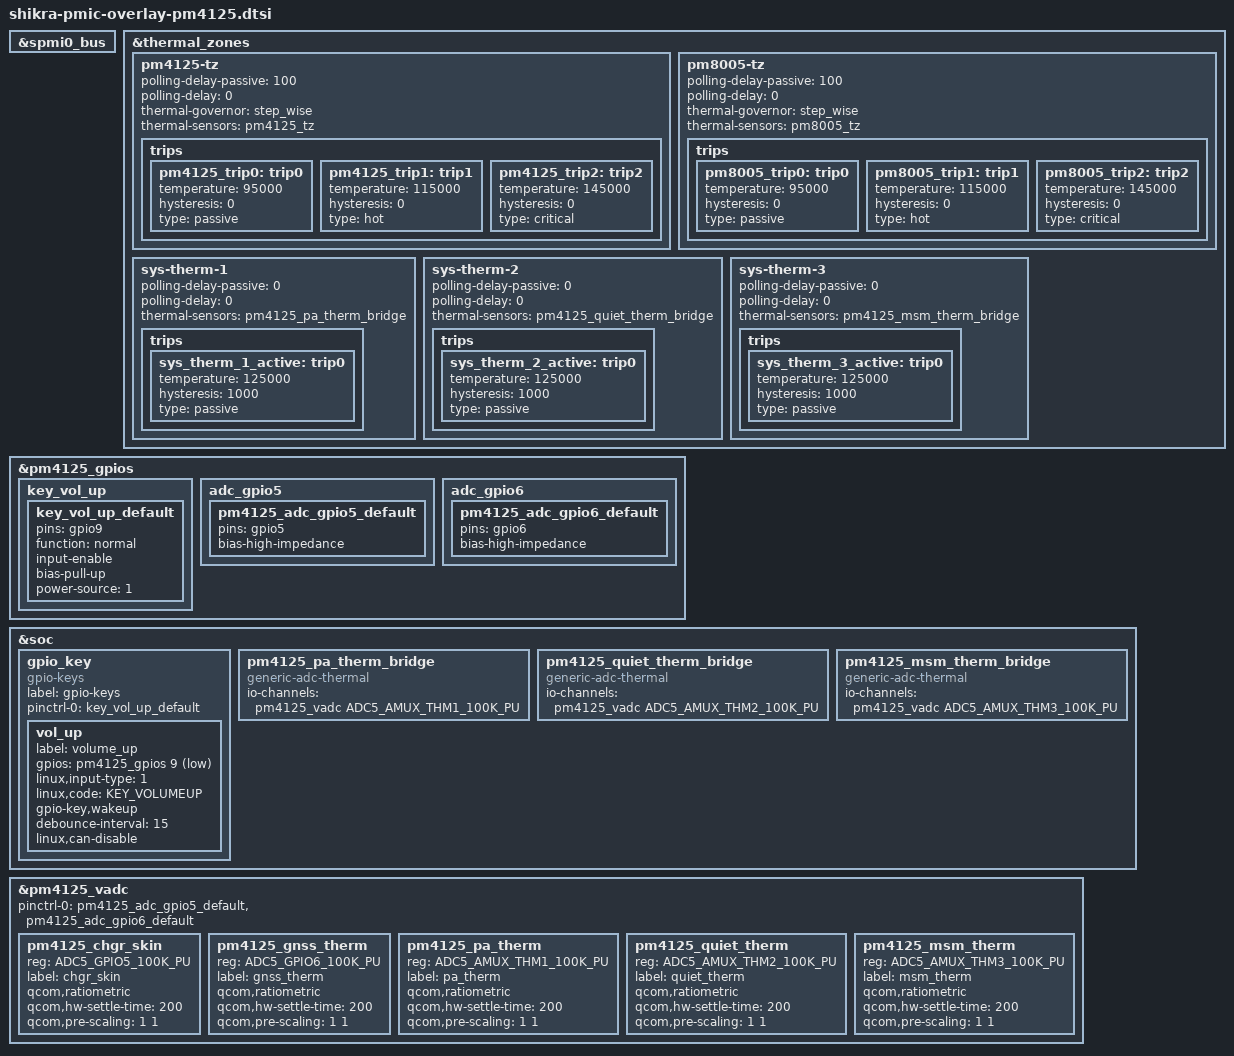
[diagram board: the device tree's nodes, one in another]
// SPDX-License-Identifier: BSD-3-Clause
/*
 * Copyright (c) Qualcomm Technologies, Inc. and/or its subsidiaries.
 */

#include <dt-bindings/gpio/gpio.h>
#include <dt-bindings/input/input.h>
#include <dt-bindings/iio/qcom,spmi-vadc.h>

&spmi0_bus {
	#include "pm4125.dtsi"
	#include "pm8005.dtsi"
};

&thermal_zones {
	pm4125-tz {
		polling-delay-passive = <100>;
		polling-delay = <0>;
		thermal-governor = "step_wise";
		thermal-sensors = <&pm4125_tz>;

		trips {
			pm4125_trip0: trip0 {
				temperature = <95000>;
				hysteresis = <0>;
				type = "passive";
			};

			pm4125_trip1: trip1 {
				temperature = <115000>;
				hysteresis = <0>;
				type = "hot";
			};

			pm4125_trip2: trip2 {
				temperature = <145000>;
				hysteresis = <0>;
				type = "critical";
			};
		};
	};

	pm8005-tz {
		polling-delay-passive = <100>;
		polling-delay = <0>;
		thermal-governor = "step_wise";
		thermal-sensors = <&pm8005_tz>;

		trips {
			pm8005_trip0: trip0 {
				temperature = <95000>;
				hysteresis = <0>;
				type = "passive";
			};

			pm8005_trip1: trip1 {
				temperature = <115000>;
				hysteresis = <0>;
				type = "hot";
			};

			pm8005_trip2: trip2 {
				temperature = <145000>;
				hysteresis = <0>;
				type = "critical";
			};
		};
	};

	sys-therm-1 {
		polling-delay-passive = <0>;
		polling-delay = <0>;
		thermal-sensors = <&pm4125_pa_therm_bridge>;

		trips {
			sys_therm_1_active: trip0 {
				temperature = <125000>;
				hysteresis = <1000>;
				type = "passive";
			};
		};
	};

	sys-therm-2 {
		polling-delay-passive = <0>;
		polling-delay = <0>;
		thermal-sensors = <&pm4125_quiet_therm_bridge>;

		trips {
			sys_therm_2_active: trip0 {
				temperature = <125000>;
				hysteresis = <1000>;
				type = "passive";
			};
		};
	};

	sys-therm-3 {
		polling-delay-passive = <0>;
		polling-delay = <0>;
		thermal-sensors = <&pm4125_msm_therm_bridge>;

		trips {
			sys_therm_3_active: trip0 {
				temperature = <125000>;
				hysteresis = <1000>;
				type = "passive";
			};
		};
	};
};

&pm4125_gpios {
	key_vol_up {
		key_vol_up_default: key_vol_up_default {
			pins = "gpio9";
			function = "normal";
			input-enable;
			bias-pull-up;
			power-source = <1>;
		};
	};

	adc_gpio5 {
		pm4125_adc_gpio5_default: pm4125_adc_gpio5_default {
			pins = "gpio5";
			bias-high-impedance;
		};
	};

	adc_gpio6 {
		pm4125_adc_gpio6_default: pm4125_adc_gpio6_default {
			pins = "gpio6";
			bias-high-impedance;
		};
	};
};

&soc {
	gpio_key {
		compatible = "gpio-keys";
		label = "gpio-keys";
		pinctrl-names = "default";
		pinctrl-0 = <&key_vol_up_default>;

		vol_up {
			label = "volume_up";
			gpios = <&pm4125_gpios 9 GPIO_ACTIVE_LOW>;
			linux,input-type = <1>;
			linux,code = <KEY_VOLUMEUP>;
			gpio-key,wakeup;
			debounce-interval = <15>;
			linux,can-disable;
		};
	};

	pm4125_pa_therm_bridge: pm4125_pa_therm_bridge {
		compatible = "generic-adc-thermal";
		io-channels = <&pm4125_vadc ADC5_AMUX_THM1_100K_PU>;
		io-channel-names = "sensor-channel";
		#thermal-sensor-cells = <0>; /* It becomes the sensor provider */
	};

	pm4125_quiet_therm_bridge: pm4125_quiet_therm_bridge {
		compatible = "generic-adc-thermal";
		io-channels = <&pm4125_vadc ADC5_AMUX_THM2_100K_PU>;
		io-channel-names = "sensor-channel";
		#thermal-sensor-cells = <0>;
	};

	pm4125_msm_therm_bridge: pm4125_msm_therm_bridge {
		compatible = "generic-adc-thermal";
		io-channels = <&pm4125_vadc ADC5_AMUX_THM3_100K_PU>;
		io-channel-names = "sensor-channel";
		#thermal-sensor-cells = <0>;
	};
};

&pm4125_vadc {
	pinctrl-0 = <&pm4125_adc_gpio5_default>, <&pm4125_adc_gpio6_default>;
	pinctrl-names = "default";

	pm4125_chgr_skin {
		reg = <ADC5_GPIO5_100K_PU>;
		label = "chgr_skin";
		qcom,ratiometric;
		qcom,hw-settle-time = <200>;
		qcom,pre-scaling = <1 1>;
	};

	pm4125_gnss_therm {
		reg = <ADC5_GPIO6_100K_PU>;
		label = "gnss_therm";
		qcom,ratiometric;
		qcom,hw-settle-time = <200>;
		qcom,pre-scaling = <1 1>;
	};

	pm4125_pa_therm {
		reg = <ADC5_AMUX_THM1_100K_PU>;
		label = "pa_therm";
		qcom,ratiometric;
		qcom,hw-settle-time = <200>;
		qcom,pre-scaling = <1 1>;
	};

	pm4125_quiet_therm {
		reg = <ADC5_AMUX_THM2_100K_PU>;
		label = "quiet_therm";
		qcom,ratiometric;
		qcom,hw-settle-time = <200>;
		qcom,pre-scaling = <1 1>;
	};

	pm4125_msm_therm {
		reg = <ADC5_AMUX_THM3_100K_PU>;
		label = "msm_therm";
		qcom,ratiometric;
		qcom,hw-settle-time = <200>;
		qcom,pre-scaling = <1 1>;
	};
};
